AUTOSAR XML (schema 00046)
package /RTE_Events_Lab
  sender receiver interface SRI_Output
    data SumResult: type=uint32
  sender receiver interface SRI_Input
    data Val1: type=uint16
    data Val2: type=uint16
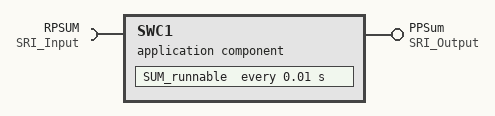
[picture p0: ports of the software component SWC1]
  application sw component type SWC1
    provide port PPSum: provided-interface=SRI_Output
    require port RPSUM: required-interface=SRI_Input
    behavior SWC1_Beh
      timing event TE_10ms: start-on-event=SUM_runnable, period=0.01
      init event InitEvent: start-on-event=SUM_runnable
      data received event DRCEvent: start-on-event=SUM_runnable, data=SUM_runnable
      data write completed event DWCEvent: start-on-event=SUM_runnable, event-source=SUMResult_Data
      runnable SUM_runnable: symbol=SUM
        data-read-access:
          access VAL1_DATA: accessed-variable=RPSUM.Val1
          access VAL2_DATA: accessed-variable=RPSUM.Val2
        data-write-access:
          access SUMResult_Data: accessed-variable=PPSum.SumResult
